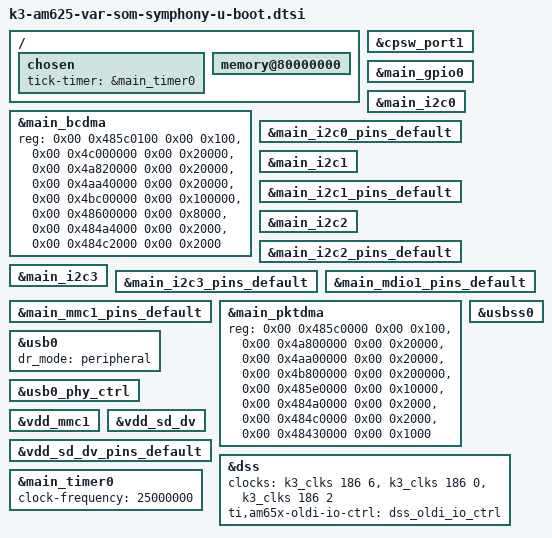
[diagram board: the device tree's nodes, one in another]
// SPDX-License-Identifier: GPL-2.0
/*
 * VAR-SOM-AM62 dts file for SPLs
 * Copyright (C) 2021-2022 Texas Instruments Incorporated - https://www.ti.com/
 * Copyright (C) 2023-2025 Variscite Ltd. - https://www.variscite.com/
 */
#include "k3-am625-var-som-symphony-binman.dtsi"

/ {
	chosen {
		tick-timer = &main_timer0;
	};

	memory@80000000 {
		bootph-all;
	};
};

&cpsw_port1 {
	/* Variscite MAC addresses assigned by EEPROM/env */
	/delete-property/ ti,syscon-efuse;
	bootph-pre-ram;
};

&main_bcdma {
	reg = <0x00 0x485c0100 0x00 0x100>,
	      <0x00 0x4c000000 0x00 0x20000>,
	      <0x00 0x4a820000 0x00 0x20000>,
	      <0x00 0x4aa40000 0x00 0x20000>,
	      <0x00 0x4bc00000 0x00 0x100000>,
	      <0x00 0x48600000 0x00 0x8000>,
	      <0x00 0x484a4000 0x00 0x2000>,
	      <0x00 0x484c2000 0x00 0x2000>;
	reg-names = "gcfg", "bchanrt", "rchanrt", "tchanrt",
		    "ringrt" , "cfg", "tchan", "rchan";
};

&main_gpio0 {
	bootph-all;
};

&main_i2c0 {
	bootph-all;
};

&main_i2c0_pins_default {
	bootph-all;
};

&main_i2c1 {
	bootph-all;
};

&main_i2c1_pins_default {
	bootph-all;
};

&main_i2c2 {
	bootph-all;
};

&main_i2c2_pins_default {
	bootph-all;
};

&main_i2c3 {
	bootph-all;
	/delete-property/ power-domains;
};

&main_i2c3_pins_default {
	bootph-all;
};

&main_mdio1_pins_default {
	bootph-pre-ram;
};

&main_mmc1_pins_default {
	bootph-pre-ram;
};

&main_pktdma {
	reg = <0x00 0x485c0000 0x00 0x100>,
	      <0x00 0x4a800000 0x00 0x20000>,
	      <0x00 0x4aa00000 0x00 0x20000>,
	      <0x00 0x4b800000 0x00 0x200000>,
	      <0x00 0x485e0000 0x00 0x10000>,
	      <0x00 0x484a0000 0x00 0x2000>,
	      <0x00 0x484c0000 0x00 0x2000>,
	      <0x00 0x48430000 0x00 0x1000>;
	reg-names = "gcfg", "rchanrt", "tchanrt", "ringrt",
		    "cfg", "tchan", "rchan", "rflow";
	bootph-all;
};

&usb0 {
	dr_mode = "peripheral";
	/* Since role switching is not supported in U-Boot */
	/delete-property/ extcon;
	bootph-all;
};

&usbss0 {
	bootph-all;
};

/* Required for USB DFU Boot */
&usb0_phy_ctrl {
	bootph-all;
};

&vdd_mmc1 {
	bootph-all;
};

&vdd_sd_dv {
	bootph-all;
};

&vdd_sd_dv_pins_default {
	bootph-all;
};

&dss {
    clocks = <&k3_clks 186 6>,
		<&k3_clks 186 0>,
		<&k3_clks 186 2>;
    ti,am65x-oldi-io-ctrl = <&dss_oldi_io_ctrl>;
};

&main_timer0 {
	clock-frequency = <25000000>;
};
